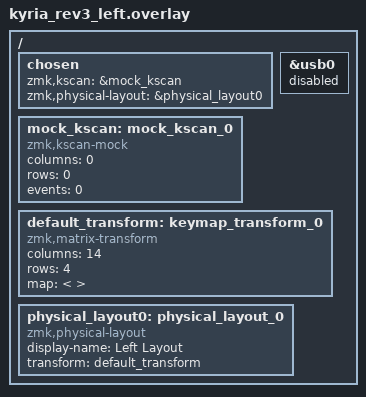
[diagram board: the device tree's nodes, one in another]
#include <dt-bindings/zmk/matrix_transform.h>

/ {
    chosen {
        zmk,kscan = &mock_kscan;
        zmk,physical-layout = &physical_layout0;
    };

    mock_kscan: mock_kscan_0 {
        compatible = "zmk,kscan-mock";
        columns = <0>;
        rows = <0>;
        events = <0>;
    };

    /* USB uitschakelen voor perifere helft */
    &usb0 {
        status = "disabled";
    };

    default_transform: keymap_transform_0 {
        compatible = "zmk,matrix-transform";
        columns = <14>;
        rows = <4>;
        map = < /* hier de keymap voor linkerhelft */ >;
    };

    physical_layout0: physical_layout_0 {
        compatible = "zmk,physical-layout";
        display-name = "Left Layout";
        transform = <&default_transform>;
    };
};
